VERSION "EmptyFile.dbc"

NS_ :

BS_:

BU_: TestNode1 TestNode2

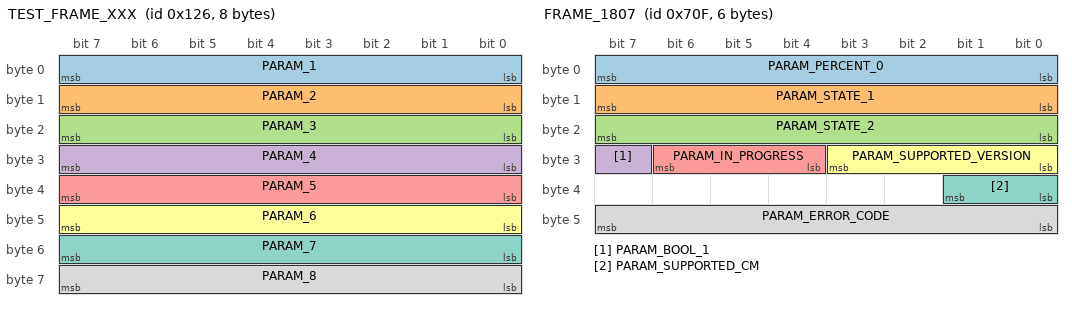
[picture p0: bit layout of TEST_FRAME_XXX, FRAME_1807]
BO_ 294 TEST_FRAME_XXX: 8 TestNode
 SG_ PARAM_1 : 7|8@0+ (1,0) [0|0] "" TestNode2
 SG_ PARAM_2 : 15|8@0+ (1,0) [0|0] "" TestNode2
 SG_ PARAM_3 : 23|8@0+ (1,0) [0|0] "" TestNode2
 SG_ PARAM_4 : 31|8@0+ (1,0) [0|0] "" TestNode2
 SG_ PARAM_5 : 39|8@0+ (1,0) [0|0] "" TestNode2
 SG_ PARAM_6 : 47|8@0+ (1,0) [0|0] "" TestNode2
 SG_ PARAM_7 : 55|8@0+ (1,0) [0|0] "" TestNode2
 SG_ PARAM_8 : 63|8@0+ (1,0) [0|0] "" TestNode2

BO_ 1800 FRAME_1800 : 3 TestNode
 SG_ PARAM_VOLTAGE_1 : 7|16@0+ (1,0) [0|0] "V" TestNode2
 SG_ PARAM_CURRENT_1 : 23|8@0+ (1,0) [0|0] "" TestNode2

BO_ 1807 FRAME_1807 : 6 TestNode
 SG_ PARAM_PERCENT_0 : 7|8@0+ (1,0) [0|0] "%" TestNode2
 SG_ PARAM_STATE_1 : 15|8@0+ (1,0) [0|0] "" TestNode2
 SG_ PARAM_STATE_2 : 23|8@0+ (1,0) [0|0] "" TestNode2
 SG_ PARAM_BOOL_1 : 31|1@0+ (1,0) [0|0] "" TestNode2
 SG_ PARAM_IN_PROGRESS : 30|3@0+ (1,0) [0|0] "" TestNode2
 SG_ PARAM_SUPPORTED_VERSION : 27|4@0+ (1,0) [0|0] "" TestNode2
 SG_ PARAM_SUPPORTED_CM : 33|2@0+ (1,0) [0|0] "" TestNode2
 SG_ PARAM_ERROR_CODE : 47|8@0+ (1,0) [0|0] "" TestNode2
